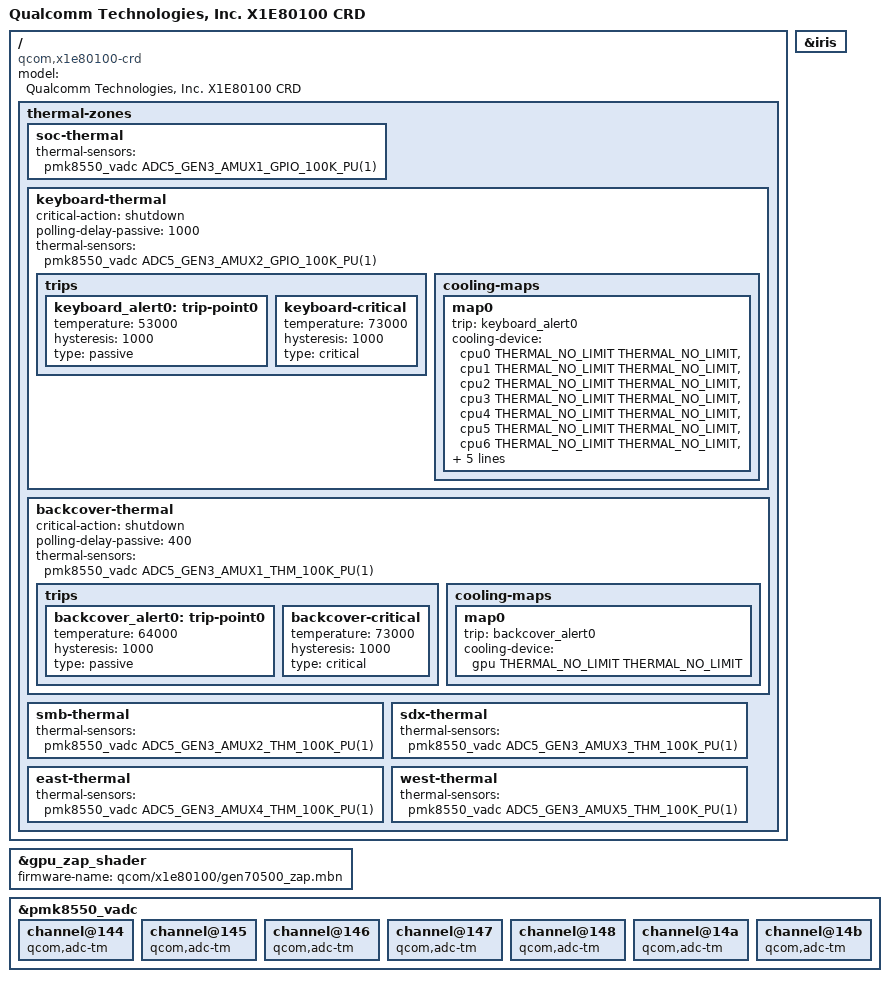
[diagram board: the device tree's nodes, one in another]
// SPDX-License-Identifier: BSD-3-Clause
/*
 * Copyright (c) 2023 Qualcomm Innovation Center, Inc. All rights reserved.
 */

/dts-v1/;

#include "hamoa.dtsi"
#include "x1-crd.dtsi"

/ {
	model = "Qualcomm Technologies, Inc. X1E80100 CRD";
	compatible = "qcom,x1e80100-crd", "qcom,x1e80100";

	thermal-zones {
		soc-thermal {
			thermal-sensors = <&pmk8550_vadc ADC5_GEN3_AMUX1_GPIO_100K_PU(1)>;
		};

		keyboard-thermal {
			critical-action = "shutdown";
			polling-delay-passive = <1000>;

			thermal-sensors = <&pmk8550_vadc ADC5_GEN3_AMUX2_GPIO_100K_PU(1)>;

			trips {
				keyboard_alert0: trip-point0 {
					temperature = <53000>;
					hysteresis = <1000>;
					type = "passive";
				};

				keyboard-critical {
					temperature = <73000>;
					hysteresis = <1000>;
					type = "critical";
				};
			};

			cooling-maps {
				map0 {
					trip = <&keyboard_alert0>;
					cooling-device = <&cpu0 THERMAL_NO_LIMIT THERMAL_NO_LIMIT>,
							 <&cpu1 THERMAL_NO_LIMIT THERMAL_NO_LIMIT>,
							 <&cpu2 THERMAL_NO_LIMIT THERMAL_NO_LIMIT>,
							 <&cpu3 THERMAL_NO_LIMIT THERMAL_NO_LIMIT>,
							 <&cpu4 THERMAL_NO_LIMIT THERMAL_NO_LIMIT>,
							 <&cpu5 THERMAL_NO_LIMIT THERMAL_NO_LIMIT>,
							 <&cpu6 THERMAL_NO_LIMIT THERMAL_NO_LIMIT>,
							 <&cpu7 THERMAL_NO_LIMIT THERMAL_NO_LIMIT>,
							 <&cpu8 THERMAL_NO_LIMIT THERMAL_NO_LIMIT>,
							 <&cpu9 THERMAL_NO_LIMIT THERMAL_NO_LIMIT>,
							 <&cpu10 THERMAL_NO_LIMIT THERMAL_NO_LIMIT>,
							 <&cpu11 THERMAL_NO_LIMIT THERMAL_NO_LIMIT>;
				};
			};
		};

		backcover-thermal {
			critical-action = "shutdown";
			polling-delay-passive = <400>;

			thermal-sensors = <&pmk8550_vadc ADC5_GEN3_AMUX1_THM_100K_PU(1)>;

			trips {
				backcover_alert0: trip-point0 {
					temperature = <64000>;
					hysteresis = <1000>;
					type = "passive";
				};

				backcover-critical {
					temperature = <73000>;
					hysteresis = <1000>;
					type = "critical";
				};
			};

			cooling-maps {
				map0 {
					trip = <&backcover_alert0>;
					cooling-device = <&gpu THERMAL_NO_LIMIT THERMAL_NO_LIMIT>;
				};
			};
		};

		smb-thermal {
			thermal-sensors = <&pmk8550_vadc ADC5_GEN3_AMUX2_THM_100K_PU(1)>;
		};

		sdx-thermal {
			thermal-sensors = <&pmk8550_vadc ADC5_GEN3_AMUX3_THM_100K_PU(1)>;
		};

		east-thermal {
			thermal-sensors = <&pmk8550_vadc ADC5_GEN3_AMUX4_THM_100K_PU(1)>;
		};

		west-thermal {
			thermal-sensors = <&pmk8550_vadc ADC5_GEN3_AMUX5_THM_100K_PU(1)>;
		};
	};
};

&gpu_zap_shader {
	firmware-name = "qcom/x1e80100/gen70500_zap.mbn";
};

&iris {
	status = "okay";
};

&pmk8550_vadc {
	channel@144 {
		qcom,adc-tm;
	};

	channel@145 {
		qcom,adc-tm;
	};

	channel@146 {
		qcom,adc-tm;
	};

	channel@147 {
		qcom,adc-tm;
	};

	channel@148 {
		qcom,adc-tm;
	};

	channel@14a {
		qcom,adc-tm;
	};

	channel@14b {
		qcom,adc-tm;
	};
};
